VERSION ""

NS_ :

BS_:

BU_: Pegasus Marvel Laptop Stark Xavier stark Gtake Pegasus Marvel Laptop Stark Xavier stark Pegasus Marvel Laptop Stark Xavier stark Gtake

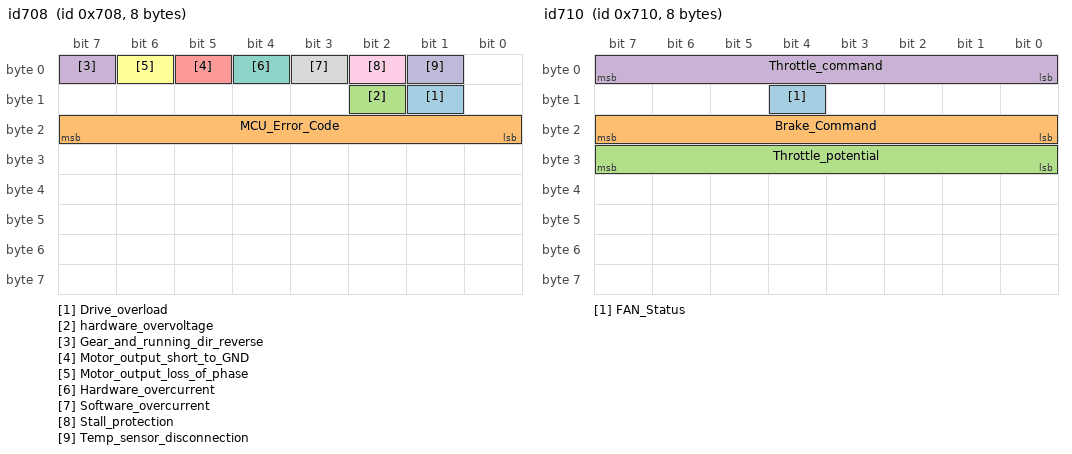
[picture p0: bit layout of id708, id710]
BO_ 1800 id708: 8 Gtake
 SG_ Drive_overload : 9|1@1+ (1,0) [0|1] "" Vector__XXX
 SG_ MCU_Error_Code : 16|8@1+ (1,0) [0|255] "" Vector__XXX
 SG_ hardware_overvoltage : 10|1@1+ (1,0) [0|1] "" Vector__XXX
 SG_ Gear_and_running_dir_reverse : 7|1@1+ (1,0) [0|1] "" Vector__XXX
 SG_ Motor_output_short_to_GND : 5|1@1+ (1,0) [0|1] "" Vector__XXX
 SG_ Motor_output_loss_of_phase : 6|1@1+ (1,0) [0|1] "" Vector__XXX
 SG_ Hardware_overcurrent : 4|1@1+ (1,0) [0|1] "" Vector__XXX
 SG_ Software_overcurrent : 3|1@1+ (1,0) [0|1] "" Vector__XXX
 SG_ Stall_protection : 2|1@1+ (1,0) [0|1] "" Vector__XXX
 SG_ Temp_sensor_disconnection : 1|1@1+ (1,0) [0|1] "" Vector__XXX

BO_ 1828 id724: 8 Gtake
 SG_ Motor_Torque_Estimated : 0|16@1- (0.1,0) [-3276.8|3276.7] "Nm" Vector__XXX

BO_ 1815 id717: 8 Gtake
 SG_ Operating_frequency : 0|16@1- (1,0) [-32768|32767] "Hz" Vector__XXX

BO_ 1814 id716: 8 Gtake
 SG_ VRMS : 40|8@1+ (1,0) [0|255] "V rms" Vector__XXX
 SG_ ARMS : 48|16@1+ (1,0) [0|65535] "A rms" Vector__XXX

BO_ 1808 id710: 8 Gtake
 SG_ FAN_Status : 12|1@1+ (1,0) [0|1] "" Vector__XXX
 SG_ Brake_Command : 16|8@1+ (1,0) [0|1] "" Vector__XXX
 SG_ Throttle_potential : 24|8@1+ (0.1,0) [0|25.5] "V" Vector__XXX
 SG_ Throttle_command : 0|8@1+ (1,0) [0|255] "%" Vector__XXX

BO_ 1813 id715: 8 Gtake
 SG_ Capacitor_Voltage : 32|8@1+ (1,0) [0|255] "V" Vector__XXX
 SG_ RPM : 48|16@1+ (1,0) [0|65535] "RPM" Vector__XXX

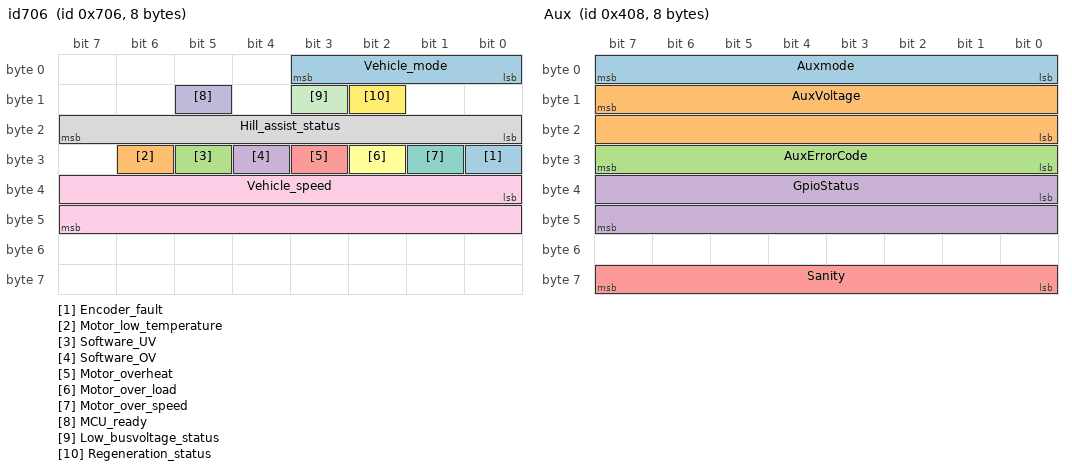
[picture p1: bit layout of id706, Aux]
BO_ 1798 id706: 8 Gtake
 SG_ Encoder_fault : 24|1@1+ (1,0) [0|1] "" Vector__XXX
 SG_ Motor_low_temperature : 30|1@1+ (1,0) [0|1] "" Vector__XXX
 SG_ Software_UV : 29|1@1+ (1,0) [0|1] "" Vector__XXX
 SG_ Software_OV : 28|1@1+ (1,0) [0|1] "" Vector__XXX
 SG_ Motor_overheat : 27|1@1+ (1,0) [0|1] "" Vector__XXX
 SG_ Motor_over_load : 26|1@1+ (1,0) [0|1] "" Vector__XXX
 SG_ Motor_over_speed : 25|1@1+ (1,0) [0|0] "" Vector__XXX
 SG_ Hill_assist_status : 16|8@1+ (1,0) [0|255] "" Vector__XXX
 SG_ Vehicle_speed : 32|16@1- (0.1,0) [-3276.8|3276.7] "Kmph" Vector__XXX
 SG_ MCU_ready : 13|1@1+ (1,0) [0|1] "" Vector__XXX
 SG_ Low_busvoltage_status : 11|1@1+ (1,0) [0|0] "" Vector__XXX
 SG_ Regeneration_status : 10|1@1+ (1,0) [0|1] "" Vector__XXX
 SG_ Vehicle_mode : 0|4@1+ (1,0) [0|15] "" Vector__XXX

BO_ 1797 id705: 8 Gtake
 SG_ MCU_Temperature : 8|8@1+ (1,-50) [-50|205] "" Vector__XXX
 SG_ Motor_Temperature : 0|8@1+ (1,-50) [-50|205] "" Vector__XXX

BO_ 1032 Aux: 8 Vector__XXX
 SG_ Auxmode : 0|8@1+ (1,0) [0|0] "" Vector__XXX
 SG_ AuxVoltage : 15|16@0+ (0.01,0) [0|0] "" Vector__XXX
 SG_ AuxErrorCode : 24|8@1+ (1,0) [0|0] "" Vector__XXX
 SG_ GpioStatus : 32|16@1+ (1,0) [0|0] "" Vector__XXX
 SG_ Sanity : 56|8@1+ (1,0) [0|0] "" Vector__XXX

BO_ 1033 Odo: 8 Vector__XXX
 SG_ Odometer : 7|32@0+ (0.01,0) [0|0] "" Vector__XXX

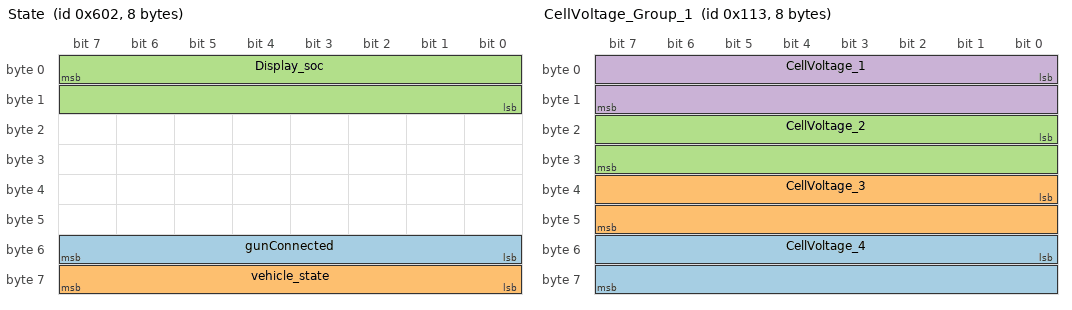
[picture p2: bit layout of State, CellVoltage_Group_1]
BO_ 1538 State: 8 Vector__XXX
 SG_ gunConnected : 48|8@1- (1,0) [0|0] "" Vector__XXX
 SG_ vehicle_state : 56|8@1+ (1,0) [0|0] "" Vector__XXX
 SG_ Display_soc : 7|16@0+ (0.1,0) [0|0] "%" Vector__XXX

BO_ 275 CellVoltage_Group_1: 8 Vector__XXX
 SG_ CellVoltage_4 : 48|16@1+ (0.1,0) [0|0] "mV" Vector__XXX
 SG_ CellVoltage_3 : 32|16@1+ (0.1,0) [0|0] "mV" Vector__XXX
 SG_ CellVoltage_2 : 16|16@1+ (0.1,0) [0|0] "mV" Vector__XXX
 SG_ CellVoltage_1 : 0|16@1+ (0.1,0) [0|0] "mV" Vector__XXX

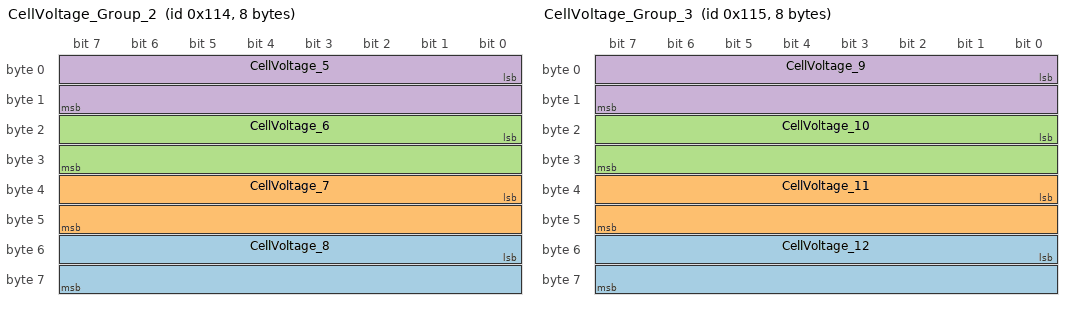
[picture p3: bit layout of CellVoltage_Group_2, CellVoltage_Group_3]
BO_ 276 CellVoltage_Group_2: 8 Vector__XXX
 SG_ CellVoltage_8 : 48|16@1+ (0.1,0) [0|0] "mV" Vector__XXX
 SG_ CellVoltage_7 : 32|16@1+ (0.1,0) [0|0] "mV" Vector__XXX
 SG_ CellVoltage_6 : 16|16@1+ (0.1,0) [0|0] "mV" Vector__XXX
 SG_ CellVoltage_5 : 0|16@1+ (0.1,0) [0|0] "mV" Vector__XXX

BO_ 277 CellVoltage_Group_3: 8 Vector__XXX
 SG_ CellVoltage_12 : 48|16@1+ (0.1,0) [0|0] "mV" Vector__XXX
 SG_ CellVoltage_11 : 32|16@1+ (0.1,0) [0|0] "mV" Vector__XXX
 SG_ CellVoltage_10 : 16|16@1+ (0.1,0) [0|0] "mV" Vector__XXX
 SG_ CellVoltage_9 : 0|16@1+ (0.1,0) [0|0] "mV" Vector__XXX

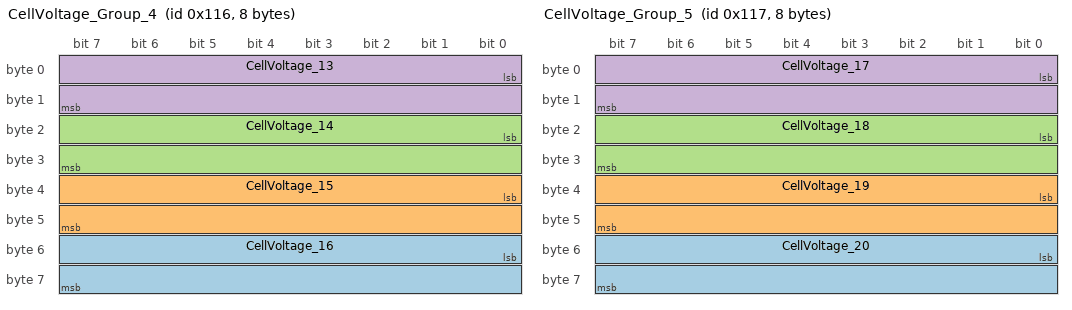
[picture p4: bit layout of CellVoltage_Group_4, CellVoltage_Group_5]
BO_ 278 CellVoltage_Group_4: 8 Vector__XXX
 SG_ CellVoltage_16 : 48|16@1+ (0.1,0) [0|0] "mV" Vector__XXX
 SG_ CellVoltage_15 : 32|16@1+ (0.1,0) [0|0] "mV" Vector__XXX
 SG_ CellVoltage_14 : 16|16@1+ (0.1,0) [0|0] "mV" Vector__XXX
 SG_ CellVoltage_13 : 0|16@1+ (0.1,0) [0|0] "mV" Vector__XXX

BO_ 279 CellVoltage_Group_5: 8 Vector__XXX
 SG_ CellVoltage_20 : 48|16@1+ (0.1,0) [0|0] "mV" Vector__XXX
 SG_ CellVoltage_19 : 32|16@1+ (0.1,0) [0|0] "mV" Vector__XXX
 SG_ CellVoltage_18 : 16|16@1+ (0.1,0) [0|0] "mV" Vector__XXX
 SG_ CellVoltage_17 : 0|16@1+ (0.1,0) [0|0] "mV" Vector__XXX

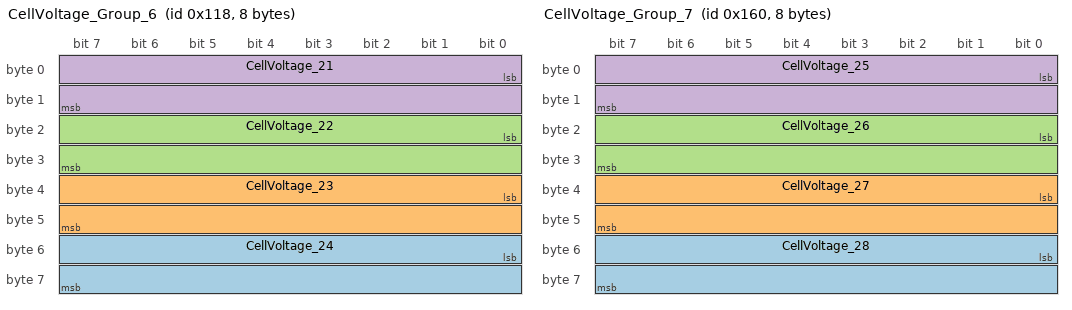
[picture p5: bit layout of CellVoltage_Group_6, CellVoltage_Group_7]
BO_ 280 CellVoltage_Group_6: 8 Vector__XXX
 SG_ CellVoltage_24 : 48|16@1+ (0.1,0) [0|0] "mV" Vector__XXX
 SG_ CellVoltage_23 : 32|16@1+ (0.1,0) [0|0] "mV" Vector__XXX
 SG_ CellVoltage_22 : 16|16@1+ (0.1,0) [0|0] "mV" Vector__XXX
 SG_ CellVoltage_21 : 0|16@1+ (0.1,0) [0|0] "mV" Vector__XXX

BO_ 352 CellVoltage_Group_7: 8 Vector__XXX
 SG_ CellVoltage_28 : 48|16@1+ (0.1,0) [0|0] "mV" Vector__XXX
 SG_ CellVoltage_27 : 32|16@1+ (0.1,0) [0|0] "mV" Vector__XXX
 SG_ CellVoltage_26 : 16|16@1+ (0.1,0) [0|0] "mV" Vector__XXX
 SG_ CellVoltage_25 : 0|16@1+ (0.1,0) [0|0] "mV" Vector__XXX

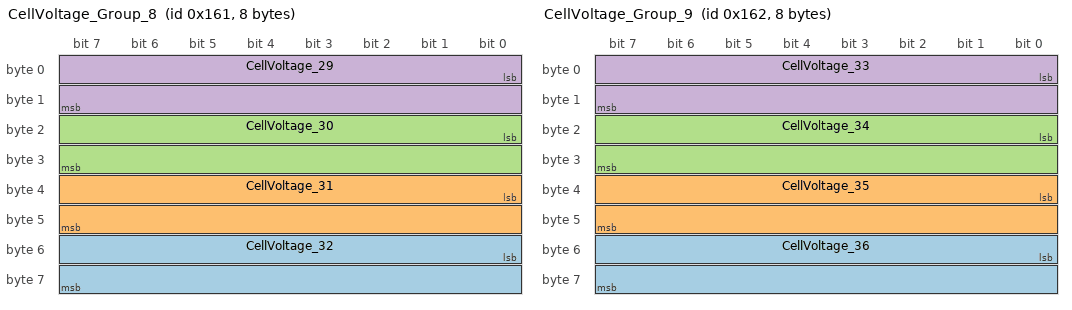
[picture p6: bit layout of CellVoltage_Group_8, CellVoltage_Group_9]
BO_ 353 CellVoltage_Group_8: 8 Vector__XXX
 SG_ CellVoltage_32 : 48|16@1+ (0.1,0) [0|0] "mV" Vector__XXX
 SG_ CellVoltage_31 : 32|16@1+ (0.1,0) [0|0] "mV" Vector__XXX
 SG_ CellVoltage_30 : 16|16@1+ (0.1,0) [0|0] "mV" Vector__XXX
 SG_ CellVoltage_29 : 0|16@1+ (0.1,0) [0|0] "mV" Vector__XXX

BO_ 354 CellVoltage_Group_9: 8 Vector__XXX
 SG_ CellVoltage_36 : 48|16@1+ (0.1,0) [0|0] "mV" Vector__XXX
 SG_ CellVoltage_35 : 32|16@1+ (0.1,0) [0|0] "mV" Vector__XXX
 SG_ CellVoltage_34 : 16|16@1+ (0.1,0) [0|0] "mV" Vector__XXX
 SG_ CellVoltage_33 : 0|16@1+ (0.1,0) [0|0] "mV" Vector__XXX

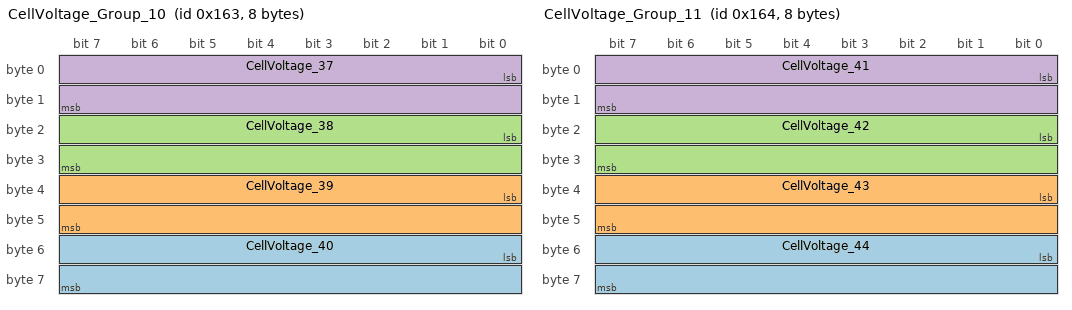
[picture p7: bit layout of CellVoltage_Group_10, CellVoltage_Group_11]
BO_ 355 CellVoltage_Group_10: 8 Vector__XXX
 SG_ CellVoltage_40 : 48|16@1+ (0.1,0) [0|0] "mV" Vector__XXX
 SG_ CellVoltage_39 : 32|16@1+ (0.1,0) [0|0] "mV" Vector__XXX
 SG_ CellVoltage_38 : 16|16@1+ (0.1,0) [0|0] "mV" Vector__XXX
 SG_ CellVoltage_37 : 0|16@1+ (0.1,0) [0|0] "mV" Vector__XXX

BO_ 356 CellVoltage_Group_11: 8 Vector__XXX
 SG_ CellVoltage_44 : 48|16@1+ (0.1,0) [0|0] "mV" Vector__XXX
 SG_ CellVoltage_43 : 32|16@1+ (0.1,0) [0|0] "mV" Vector__XXX
 SG_ CellVoltage_42 : 16|16@1+ (0.1,0) [0|0] "mV" Vector__XXX
 SG_ CellVoltage_41 : 0|16@1+ (0.1,0) [0|0] "mV" Vector__XXX

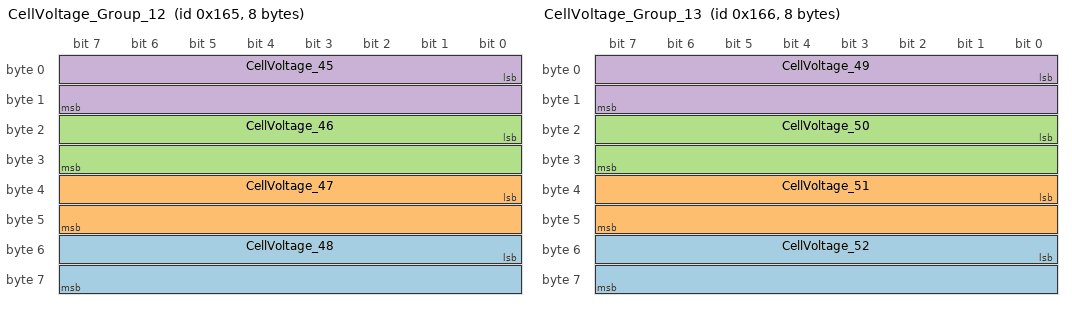
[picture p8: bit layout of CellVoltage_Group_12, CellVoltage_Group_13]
BO_ 357 CellVoltage_Group_12: 8 Vector__XXX
 SG_ CellVoltage_48 : 48|16@1+ (0.1,0) [0|0] "mV" Vector__XXX
 SG_ CellVoltage_47 : 32|16@1+ (0.1,0) [0|0] "mV" Vector__XXX
 SG_ CellVoltage_46 : 16|16@1+ (0.1,0) [0|0] "mV" Vector__XXX
 SG_ CellVoltage_45 : 0|16@1+ (0.1,0) [0|0] "mV" Vector__XXX

BO_ 358 CellVoltage_Group_13: 8 Vector__XXX
 SG_ CellVoltage_52 : 48|16@1+ (0.1,0) [0|0] "mV" Vector__XXX
 SG_ CellVoltage_51 : 32|16@1+ (0.1,0) [0|0] "mV" Vector__XXX
 SG_ CellVoltage_50 : 16|16@1+ (0.1,0) [0|0] "mV" Vector__XXX
 SG_ CellVoltage_49 : 0|16@1+ (0.1,0) [0|0] "mV" Vector__XXX

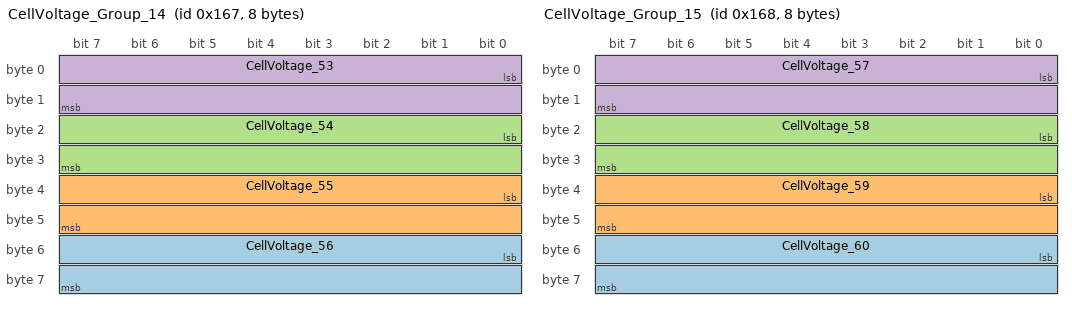
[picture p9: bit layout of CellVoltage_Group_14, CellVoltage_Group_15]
BO_ 359 CellVoltage_Group_14: 8 Vector__XXX
 SG_ CellVoltage_56 : 48|16@1+ (0.1,0) [0|0] "mV" Vector__XXX
 SG_ CellVoltage_55 : 32|16@1+ (0.1,0) [0|0] "mV" Vector__XXX
 SG_ CellVoltage_54 : 16|16@1+ (0.1,0) [0|0] "mV" Vector__XXX
 SG_ CellVoltage_53 : 0|16@1+ (0.1,0) [0|0] "mV" Vector__XXX

BO_ 360 CellVoltage_Group_15: 8 Vector__XXX
 SG_ CellVoltage_60 : 48|16@1+ (0.1,0) [0|0] "mV" Vector__XXX
 SG_ CellVoltage_59 : 32|16@1+ (0.1,0) [0|0] "mV" Vector__XXX
 SG_ CellVoltage_58 : 16|16@1+ (0.1,0) [0|0] "mV" Vector__XXX
 SG_ CellVoltage_57 : 0|16@1+ (0.1,0) [0|0] "mV" Vector__XXX

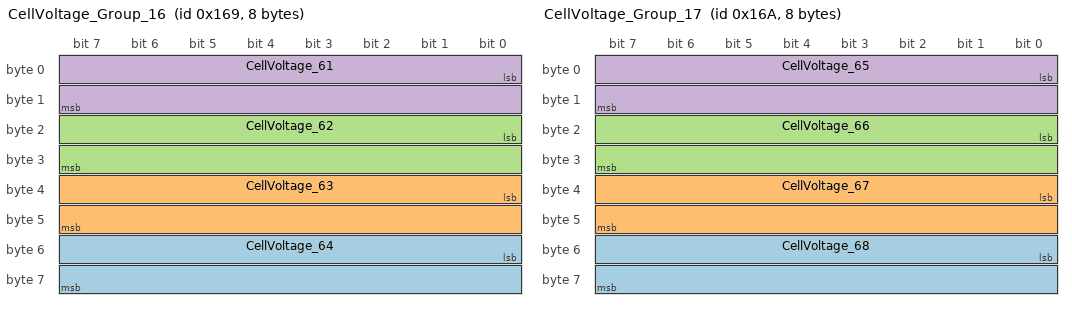
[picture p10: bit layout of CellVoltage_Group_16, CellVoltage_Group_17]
BO_ 361 CellVoltage_Group_16: 8 Vector__XXX
 SG_ CellVoltage_64 : 48|16@1+ (0.1,0) [0|0] "mV" Vector__XXX
 SG_ CellVoltage_63 : 32|16@1+ (0.1,0) [0|0] "mV" Vector__XXX
 SG_ CellVoltage_62 : 16|16@1+ (0.1,0) [0|0] "mV" Vector__XXX
 SG_ CellVoltage_61 : 0|16@1+ (0.1,0) [0|0] "mV" Vector__XXX

BO_ 362 CellVoltage_Group_17: 8 Vector__XXX
 SG_ CellVoltage_68 : 48|16@1+ (0.1,0) [0|0] "mV" Vector__XXX
 SG_ CellVoltage_67 : 32|16@1+ (0.1,0) [0|0] "mV" Vector__XXX
 SG_ CellVoltage_66 : 16|16@1+ (0.1,0) [0|0] "mV" Vector__XXX
 SG_ CellVoltage_65 : 0|16@1+ (0.1,0) [0|0] "mV" Vector__XXX

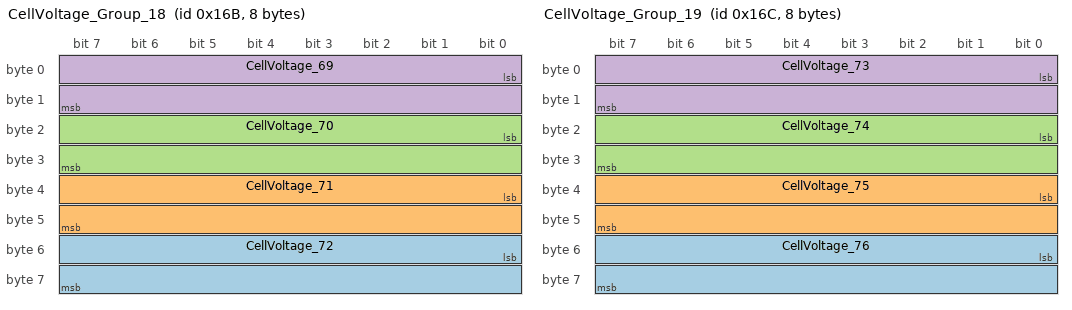
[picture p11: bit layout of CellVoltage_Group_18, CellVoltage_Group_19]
BO_ 363 CellVoltage_Group_18: 8 Vector__XXX
 SG_ CellVoltage_72 : 48|16@1+ (0.1,0) [0|0] "mV" Vector__XXX
 SG_ CellVoltage_71 : 32|16@1+ (0.1,0) [0|0] "mV" Vector__XXX
 SG_ CellVoltage_70 : 16|16@1+ (0.1,0) [0|0] "mV" Vector__XXX
 SG_ CellVoltage_69 : 0|16@1+ (0.1,0) [0|0] "mV" Vector__XXX

BO_ 364 CellVoltage_Group_19: 8 Vector__XXX
 SG_ CellVoltage_76 : 48|16@1+ (0.1,0) [0|0] "mV" Vector__XXX
 SG_ CellVoltage_75 : 32|16@1+ (0.1,0) [0|0] "mV" Vector__XXX
 SG_ CellVoltage_74 : 16|16@1+ (0.1,0) [0|0] "mV" Vector__XXX
 SG_ CellVoltage_73 : 0|16@1+ (0.1,0) [0|0] "mV" Vector__XXX

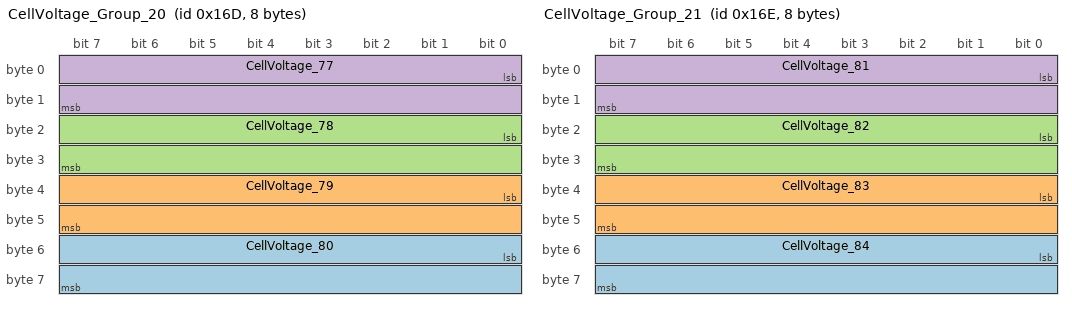
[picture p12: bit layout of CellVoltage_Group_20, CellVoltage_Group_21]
BO_ 365 CellVoltage_Group_20: 8 Vector__XXX
 SG_ CellVoltage_80 : 48|16@1+ (0.1,0) [0|0] "mV" Vector__XXX
 SG_ CellVoltage_79 : 32|16@1+ (0.1,0) [0|0] "mV" Vector__XXX
 SG_ CellVoltage_78 : 16|16@1+ (0.1,0) [0|0] "mV" Vector__XXX
 SG_ CellVoltage_77 : 0|16@1+ (0.1,0) [0|0] "mV" Vector__XXX

BO_ 366 CellVoltage_Group_21: 8 Vector__XXX
 SG_ CellVoltage_84 : 48|16@1+ (0.1,0) [0|0] "mV" Vector__XXX
 SG_ CellVoltage_83 : 32|16@1+ (0.1,0) [0|0] "mV" Vector__XXX
 SG_ CellVoltage_82 : 16|16@1+ (0.1,0) [0|0] "mV" Vector__XXX
 SG_ CellVoltage_81 : 0|16@1+ (0.1,0) [0|0] "mV" Vector__XXX

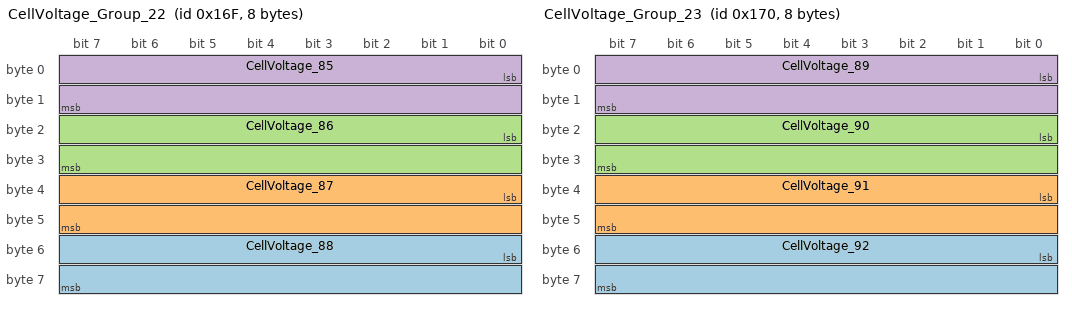
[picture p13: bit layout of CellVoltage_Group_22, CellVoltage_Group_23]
BO_ 367 CellVoltage_Group_22: 8 Vector__XXX
 SG_ CellVoltage_88 : 48|16@1+ (0.1,0) [0|0] "mV" Vector__XXX
 SG_ CellVoltage_87 : 32|16@1+ (0.1,0) [0|0] "mV" Vector__XXX
 SG_ CellVoltage_86 : 16|16@1+ (0.1,0) [0|0] "mV" Vector__XXX
 SG_ CellVoltage_85 : 0|16@1+ (0.1,0) [0|0] "mV" Vector__XXX

BO_ 368 CellVoltage_Group_23: 8 Vector__XXX
 SG_ CellVoltage_92 : 48|16@1+ (0.1,0) [0|0] "mV" Vector__XXX
 SG_ CellVoltage_91 : 32|16@1+ (0.1,0) [0|0] "mV" Vector__XXX
 SG_ CellVoltage_90 : 16|16@1+ (0.1,0) [0|0] "mV" Vector__XXX
 SG_ CellVoltage_89 : 0|16@1+ (0.1,0) [0|0] "mV" Vector__XXX

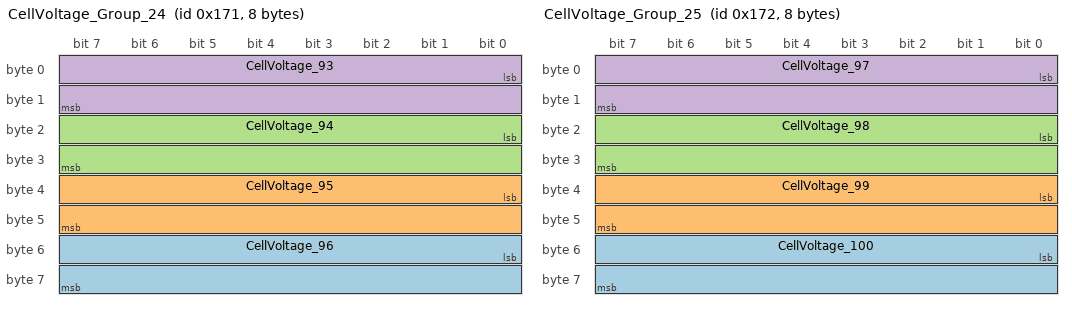
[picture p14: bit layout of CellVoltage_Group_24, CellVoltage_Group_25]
BO_ 369 CellVoltage_Group_24: 8 Vector__XXX
 SG_ CellVoltage_96 : 48|16@1+ (0.1,0) [0|0] "mV" Vector__XXX
 SG_ CellVoltage_95 : 32|16@1+ (0.1,0) [0|0] "mV" Vector__XXX
 SG_ CellVoltage_94 : 16|16@1+ (0.1,0) [0|0] "mV" Vector__XXX
 SG_ CellVoltage_93 : 0|16@1+ (0.1,0) [0|0] "mV" Vector__XXX

BO_ 370 CellVoltage_Group_25: 8 Vector__XXX
 SG_ CellVoltage_100 : 48|16@1+ (0.1,0) [0|0] "mV" Vector__XXX
 SG_ CellVoltage_99 : 32|16@1+ (0.1,0) [0|0] "mV" Vector__XXX
 SG_ CellVoltage_98 : 16|16@1+ (0.1,0) [0|0] "mV" Vector__XXX
 SG_ CellVoltage_97 : 0|16@1+ (0.1,0) [0|0] "mV" Vector__XXX

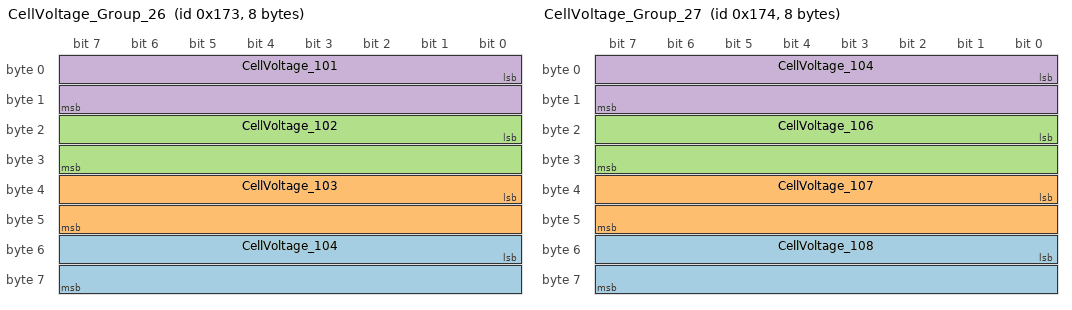
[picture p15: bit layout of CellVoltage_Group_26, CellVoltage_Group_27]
BO_ 371 CellVoltage_Group_26: 8 Vector__XXX
 SG_ CellVoltage_104 : 48|16@1+ (0.1,0) [0|0] "mV" Vector__XXX
 SG_ CellVoltage_103 : 32|16@1+ (0.1,0) [0|0] "mV" Vector__XXX
 SG_ CellVoltage_102 : 16|16@1+ (0.1,0) [0|0] "mV" Vector__XXX
 SG_ CellVoltage_101 : 0|16@1+ (0.1,0) [0|0] "mV" Vector__XXX

BO_ 372 CellVoltage_Group_27: 8 Vector__XXX
 SG_ CellVoltage_108 : 48|16@1+ (0.1,0) [0|0] "mV" Vector__XXX
 SG_ CellVoltage_107 : 32|16@1+ (0.1,0) [0|0] "mV" Vector__XXX
 SG_ CellVoltage_106 : 16|16@1+ (0.1,0) [0|0] "mV" Vector__XXX
 SG_ CellVoltage_104 : 0|16@1+ (0.1,0) [0|0] "mV" Vector__XXX

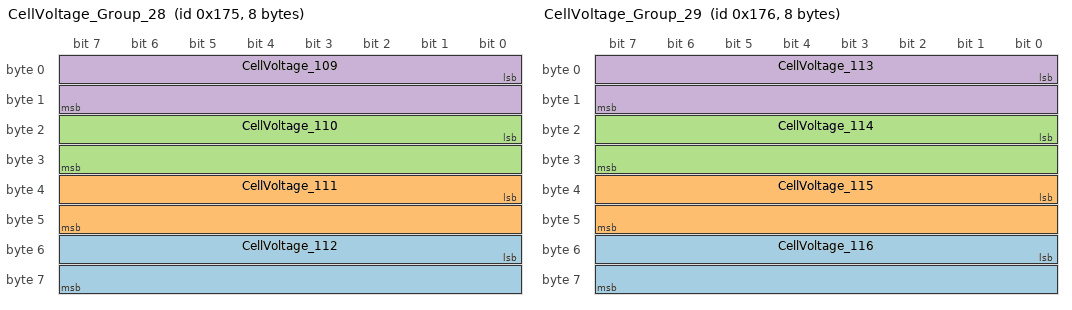
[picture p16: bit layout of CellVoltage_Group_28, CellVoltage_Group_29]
BO_ 373 CellVoltage_Group_28: 8 Vector__XXX
 SG_ CellVoltage_112 : 48|16@1+ (0.1,0) [0|0] "mV" Vector__XXX
 SG_ CellVoltage_111 : 32|16@1+ (0.1,0) [0|0] "mV" Vector__XXX
 SG_ CellVoltage_110 : 16|16@1+ (0.1,0) [0|0] "mV" Vector__XXX
 SG_ CellVoltage_109 : 0|16@1+ (0.1,0) [0|0] "mV" Vector__XXX

BO_ 374 CellVoltage_Group_29: 8 Vector__XXX
 SG_ CellVoltage_116 : 48|16@1+ (0.1,0) [0|0] "mV" Vector__XXX
 SG_ CellVoltage_115 : 32|16@1+ (0.1,0) [0|0] "mV" Vector__XXX
 SG_ CellVoltage_114 : 16|16@1+ (0.1,0) [0|0] "mV" Vector__XXX
 SG_ CellVoltage_113 : 0|16@1+ (0.1,0) [0|0] "mV" Vector__XXX

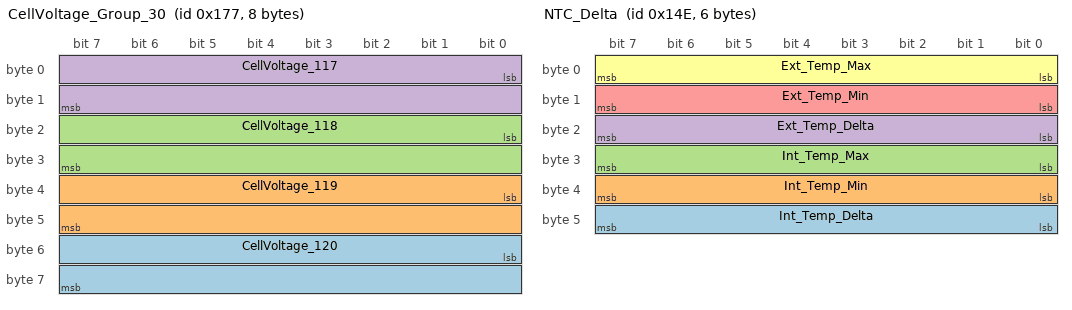
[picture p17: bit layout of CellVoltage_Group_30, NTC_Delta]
BO_ 375 CellVoltage_Group_30: 8 Vector__XXX
 SG_ CellVoltage_120 : 48|16@1+ (0.1,0) [0|0] "mV" Vector__XXX
 SG_ CellVoltage_119 : 32|16@1+ (0.1,0) [0|0] "mV" Vector__XXX
 SG_ CellVoltage_118 : 16|16@1+ (0.1,0) [0|0] "mV" Vector__XXX
 SG_ CellVoltage_117 : 0|16@1+ (0.1,0) [0|0] "mV" Vector__XXX

BO_ 274 ExtTherm_Capacity_Group_1: 8 Vector__XXX
 SG_ Pack_Capacity : 48|16@1- (0.01,0) [0|0] "Ah" Vector__XXX

BO_ 334 NTC_Delta: 6 Vector__XXX
 SG_ Int_Temp_Delta : 40|8@1- (1,0) [-128|127] "degC" Vector__XXX
 SG_ Int_Temp_Min : 32|8@1- (1,0) [-128|127] "degC" Vector__XXX
 SG_ Int_Temp_Max : 24|8@1- (1,0) [-128|127] "degC" Vector__XXX
 SG_ Ext_Temp_Delta : 16|8@1- (1,0) [-128|127] "degC" Vector__XXX
 SG_ Ext_Temp_Min : 8|8@1- (1,0) [-128|127] "degC" Vector__XXX
 SG_ Ext_Temp_Max : 0|8@1- (1,0) [-128|127] "degC" Vector__XXX

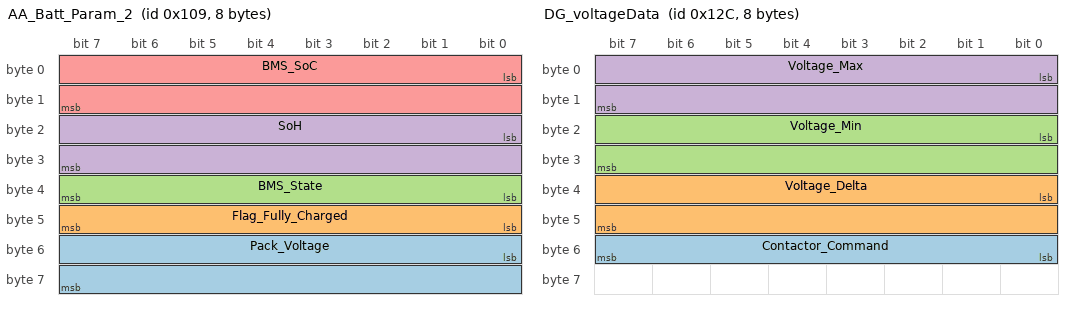
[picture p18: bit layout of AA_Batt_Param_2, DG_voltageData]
BO_ 265 AA_Batt_Param_2: 8 Vector__XXX
 SG_ Pack_Voltage : 48|16@1+ (0.1,0) [0|0] "V" Vector__XXX
 SG_ Flag_Fully_Charged : 40|8@1+ (1,0) [0|0] "" Vector__XXX
 SG_ BMS_State : 32|8@1+ (1,0) [0|0] "" Vector__XXX
 SG_ SoH : 16|16@1+ (0.01,0) [0|0] "%" Vector__XXX
 SG_ BMS_SoC : 0|16@1+ (0.01,0) [0|0] "%" Vector__XXX

BO_ 272 AC_Batt_Param_3: 8 Vector__XXX
 SG_ Pack_Current : 32|32@1- (1E-05,0) [0|0] "A" Vector__XXX
 SG_ Flag_Balancing_Active : 24|8@1+ (1,0) [0|0] "" Vector__XXX
 SG_ Balancing_Limit : 0|16@1+ (0.1,0) [0|0] "mV" Vector__XXX

BO_ 300 DG_voltageData: 8 Vector__XXX
 SG_ Contactor_Command : 48|8@1+ (1,0) [0|0] "" Vector__XXX
 SG_ Voltage_Delta : 32|16@1+ (0.1,0) [0|0] "mV" Vector__XXX
 SG_ Voltage_Min : 16|16@1+ (0.1,0) [0|0] "mV" Vector__XXX
 SG_ Voltage_Max : 0|16@1+ (0.1,0) [0|0] "mV" Vector__XXX

BO_ 298 BB_Dynamic_Limits: 8 Vector__XXX
 SG_ ConfigID : 48|8@1+ (1,0) [0|0] "" Vector__XXX
 SG_ DCLO : 16|16@1+ (0.1,0) [0|0] "A" Vector__XXX
 SG_ DCLI : 0|16@1+ (0.1,0) [0|0] "A" Vector__XXX

BO_ 1954 Short_Circuit_Detect: 8 Vector__XXX
 SG_ SCD_Flag : 56|8@1+ (1,0) [0|0] "" Vector__XXX

BO_ 302 IR_PARAM_1: 8 Vector__XXX
 SG_ IR_Value : 0|32@1+ (10000,0) [0|0] "" Vector__XXX

BO_ 342 BC_Dynamic_inst: 8 Vector__XXX
 SG_ dynamicLimitOut_Inst : 16|16@1+ (0.1,0) [0|0] "A" Vector__XXX
 SG_ dynamicLimitIn_Inst : 0|16@1+ (0.1,0) [0|0] "" Vector__XXX

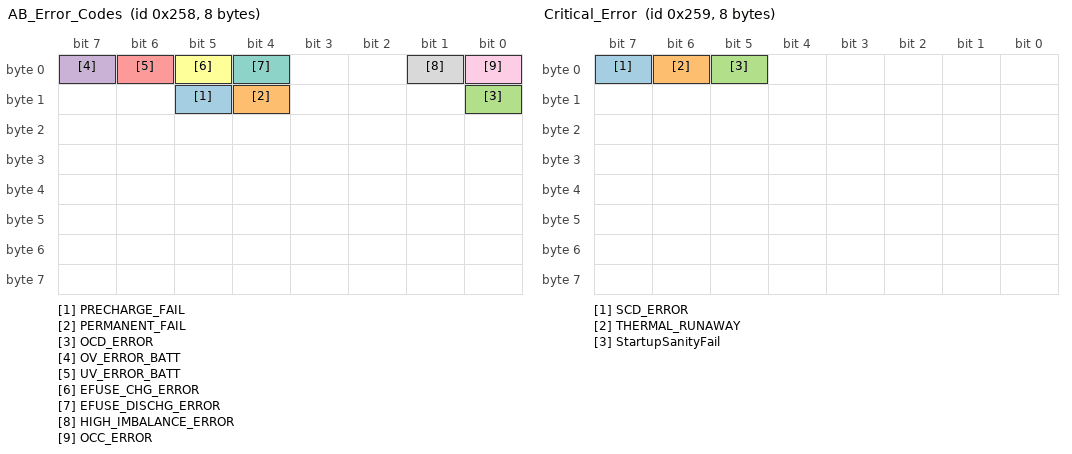
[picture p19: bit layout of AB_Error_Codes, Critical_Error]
BO_ 600 AB_Error_Codes: 8 Vector__XXX
 SG_ PRECHARGE_FAIL : 13|1@1+ (1,0) [0|0] "" Vector__XXX
 SG_ PERMANENT_FAIL : 12|1@1+ (1,0) [0|0] "" Vector__XXX
 SG_ OCD_ERROR : 8|1@1+ (1,0) [0|0] "" Vector__XXX
 SG_ OV_ERROR_BATT : 7|1@1+ (1,0) [0|0] "" Vector__XXX
 SG_ UV_ERROR_BATT : 6|1@1+ (1,0) [0|0] "" Vector__XXX
 SG_ EFUSE_CHG_ERROR : 5|1@1+ (1,0) [0|0] "" Vector__XXX
 SG_ EFUSE_DISCHG_ERROR : 4|1@1+ (1,0) [0|0] "" Vector__XXX
 SG_ HIGH_IMBALANCE_ERROR : 1|1@1+ (1,0) [0|0] "" Vector__XXX
 SG_ OCC_ERROR : 0|1@1+ (1,0) [0|0] "" Vector__XXX

BO_ 601 Critical_Error: 8 Vector__XXX
 SG_ SCD_ERROR : 7|1@1+ (1,0) [0|0] "" Vector__XXX
 SG_ THERMAL_RUNAWAY : 6|1@1+ (1,0) [0|0] "" Vector__XXX
 SG_ StartupSanityFail : 5|1@1+ (1,0) [0|0] "" Vector__XXX

BA_DEF_ SG_  "SigType" ENUM  "Default","Range","RangeSigned","ASCII","Discrete","Control","ReferencePGN","DTC","StringDelimiter","StringLength","StringLengthControl","MessageCounter","MessageChecksum";
BA_DEF_ SG_  "GenSigSendType" ENUM  "Cyclic","OnWrite","OnWriteWithRepetition","OnChange","OnChangeWithRepetition","IfActive","IfActiveWithRepetition","NoSigSendType";
BA_DEF_ SG_  "GenSigStartValue" INT 0 2147483647;
BA_DEF_ BO_  "GenMsgSendType" ENUM  "cyclic","NotUsed","IfActive","NotUsed","NotUsed","NotUsed","NotUsed","NotUsed","noMsgSendType";
BA_DEF_  "DBName" STRING ;
BA_DEF_ BO_  "VFrameFormat" ENUM  "StandardCAN","ExtendedCAN","reserved","J1939PG";
BA_DEF_ SG_  "SigType" ENUM  "Default","Range","RangeSigned","ASCII","Discrete","Control","ReferencePGN","DTC","StringDelimiter","StringLength","StringLengthControl","MessageCounter","MessageChecksum";
BA_DEF_ SG_  "GenSigSendType" ENUM  "Cyclic","OnWrite","OnWriteWithRepetition","OnChange","OnChangeWithRepetition","IfActive","IfActiveWithRepetition","NoSigSendType";
BA_DEF_ SG_  "GenSigStartValue" INT 0 2147483647;
BA_DEF_ BO_  "GenMsgSendType" ENUM  "cyclic","NotUsed","IfActive","NotUsed","NotUsed","NotUsed","NotUsed","NotUsed","noMsgSendType";
BA_DEF_  "DBName" STRING ;
BA_DEF_ BO_  "VFrameFormat" ENUM  "StandardCAN","ExtendedCAN","reserved","J1939PG";
BA_DEF_ SG_  "SigType" ENUM  "Default","Range","RangeSigned","ASCII","Discrete","Control","ReferencePGN","DTC","StringDelimiter","StringLength","StringLengthControl","MessageCounter","MessageChecksum";
BA_DEF_ SG_  "GenSigSendType" ENUM  "Cyclic","OnWrite","OnWriteWithRepetition","OnChange","OnChangeWithRepetition","IfActive","IfActiveWithRepetition","NoSigSendType";
BA_DEF_ SG_  "GenSigStartValue" INT 0 2147483647;
BA_DEF_ BO_  "GenMsgSendType" ENUM  "cyclic","NotUsed","IfActive","NotUsed","NotUsed","NotUsed","NotUsed","NotUsed","noMsgSendType";
BA_DEF_  "DBName" STRING ;
BA_DEF_ BO_  "VFrameFormat" ENUM  "StandardCAN","ExtendedCAN","reserved","J1939PG";
BA_DEF_ SG_  "SigType" ENUM  "Default","Range","RangeSigned","ASCII","Discrete","Control","ReferencePGN","DTC","StringDelimiter","StringLength","StringLengthControl","MessageCounter","MessageChecksum";
BA_DEF_ SG_  "GenSigSendType" ENUM  "Cyclic","OnWrite","OnWriteWithRepetition","OnChange","OnChangeWithRepetition","IfActive","IfActiveWithRepetition","NoSigSendType";
BA_DEF_ SG_  "GenSigStartValue" INT 0 2147483647;
BA_DEF_ BO_  "GenMsgSendType" ENUM  "cyclic","NotUsed","IfActive","NotUsed","NotUsed","NotUsed","NotUsed","NotUsed","noMsgSendType";
BA_DEF_  "DBName" STRING ;
BA_DEF_ BO_  "VFrameFormat" ENUM  "StandardCAN","ExtendedCAN","reserved","J1939PG";
BA_DEF_ SG_  "SigType" ENUM  "Default","Range","RangeSigned","ASCII","Discrete","Control","ReferencePGN","DTC","StringDelimiter","StringLength","StringLengthControl","MessageCounter","MessageChecksum";
BA_DEF_ SG_  "GenSigSendType" ENUM  "Cyclic","OnWrite","OnWriteWithRepetition","OnChange","OnChangeWithRepetition","IfActive","IfActiveWithRepetition","NoSigSendType";
BA_DEF_ SG_  "GenSigStartValue" INT 0 2147483647;
BA_DEF_ BO_  "GenMsgSendType" ENUM  "cyclic","NotUsed","IfActive","NotUsed","NotUsed","NotUsed","NotUsed","NotUsed","noMsgSendType";
BA_DEF_  "DBName" STRING ;
BA_DEF_ BO_  "VFrameFormat" ENUM  "StandardCAN","ExtendedCAN","reserved","J1939PG";
BA_DEF_DEF_  "SigType" "Default";
BA_DEF_DEF_  "GenSigSendType" "Cyclic";
BA_DEF_DEF_  "GenSigStartValue" 0;
BA_DEF_DEF_  "GenMsgSendType" "cyclic";
BA_DEF_DEF_  "DBName" "";
BA_DEF_DEF_  "VFrameFormat" "StandardCAN";
BA_DEF_DEF_  "SigType" "Default";
BA_DEF_DEF_  "GenSigSendType" "Cyclic";
BA_DEF_DEF_  "GenSigStartValue" 0;
BA_DEF_DEF_  "GenMsgSendType" "cyclic";
BA_DEF_DEF_  "DBName" "";
BA_DEF_DEF_  "VFrameFormat" "StandardCAN";
BA_DEF_DEF_  "SigType" "Default";
BA_DEF_DEF_  "GenSigSendType" "Cyclic";
BA_DEF_DEF_  "GenSigStartValue" 0;
BA_DEF_DEF_  "GenMsgSendType" "cyclic";
BA_DEF_DEF_  "DBName" "";
BA_DEF_DEF_  "VFrameFormat" "StandardCAN";
BA_DEF_DEF_  "SigType" "Default";
BA_DEF_DEF_  "GenSigSendType" "Cyclic";
BA_DEF_DEF_  "GenSigStartValue" 0;
BA_DEF_DEF_  "GenMsgSendType" "cyclic";
BA_DEF_DEF_  "DBName" "";
BA_DEF_DEF_  "VFrameFormat" "StandardCAN";
BA_DEF_DEF_  "SigType" "Default";
BA_DEF_DEF_  "GenSigSendType" "Cyclic";
BA_DEF_DEF_  "GenSigStartValue" 0;
BA_DEF_DEF_  "GenMsgSendType" "cyclic";
BA_DEF_DEF_  "DBName" "";
BA_DEF_DEF_  "VFrameFormat" "StandardCAN";
BA_ "DBName" "D03CAN";
BA_ "DBName" "D03CAN";
BA_ "DBName" "D03CAN";
BA_ "DBName" "D03CAN";
BA_ "DBName" "D03CAN";
BA_ "GenSigStartValue" SG_ 1797 MCU_Temperature 50;
BA_ "GenSigStartValue" SG_ 1797 MCU_Temperature 50;
BA_ "GenSigStartValue" SG_ 1797 MCU_Temperature 50;
BA_ "GenSigStartValue" SG_ 1797 Motor_Temperature 50;
BA_ "GenSigStartValue" SG_ 1797 Motor_Temperature 50;
BA_ "GenSigStartValue" SG_ 1797 Motor_Temperature 50;
VAL_ 1800 Drive_overload 1 "1" 0 "0" ;
VAL_ 1800 Gear_and_running_dir_reverse 1 "1" 0 "0" ;
VAL_ 1800 Motor_output_short_to_GND 1 "1" 0 "0" ;
VAL_ 1800 Motor_output_loss_of_phase 1 "1" 0 "0" ;
VAL_ 1800 Hardware_overcurrent 1 "1" 0 "0" ;
VAL_ 1800 Software_overcurrent 1 "1" 0 "0" ;
VAL_ 1800 Stall_protection 1 "1" 0 "0" ;
VAL_ 1800 Temp_sensor_disconnection 1 "1" 0 "0" ;
VAL_ 1808 Brake_Command 1 "1" 0 "0" ;
VAL_ 1798 Encoder_fault 1 "1" 0 "0" ;
VAL_ 1798 Motor_low_temperature 1 "1" 0 "0" ;
VAL_ 1798 Software_UV 1 "1" 0 "0" ;
VAL_ 1798 Software_OV 1 "1" 0 "0" ;
VAL_ 1798 Motor_overheat 1 "1" 0 "0" ;
VAL_ 1798 Motor_over_load 1 "1" 0 "0" ;
VAL_ 1798 Motor_over_speed 1 "1" 0 "0" ;
VAL_ 1798 MCU_ready 1 "1" 0 "0" ;
VAL_ 1798 Low_busvoltage_status 1 "1" 0 "0" ;
VAL_ 1798 Regeneration_status 1 "1" 0 "0" ;
VAL_ 1798 Vehicle_mode 8 "Thunder" 4 "Reverse" 2 "Eco" 1 "Neutral" ;
VAL_ 1538 vehicle_state 0 "0" 1 "1" 2 "2" 3 "3" ;
